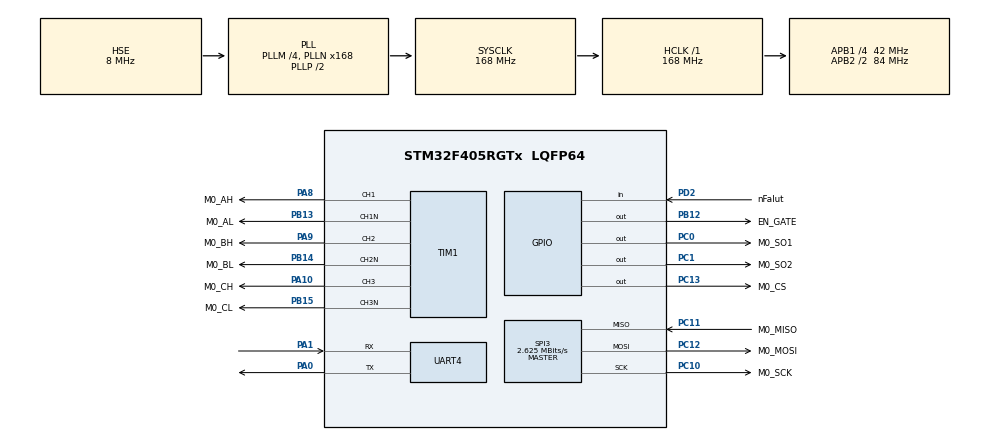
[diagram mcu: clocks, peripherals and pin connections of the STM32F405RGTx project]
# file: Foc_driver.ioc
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Dma.Request0=SPI3_RX
Dma.Request1=SPI3_TX
Dma.SPI3_RX.0.Direction=DMA_PERIPH_TO_MEMORY
Dma.SPI3_RX.0.FIFOMode=DMA_FIFOMODE_DISABLE
Dma.SPI3_RX.0.Instance=DMA1_Stream0
Dma.SPI3_RX.0.MemDataAlignment=DMA_MDATAALIGN_HALFWORD
Dma.SPI3_RX.0.MemInc=DMA_MINC_ENABLE
Dma.SPI3_RX.0.Mode=DMA_NORMAL
Dma.SPI3_RX.0.PeriphDataAlignment=DMA_PDATAALIGN_HALFWORD
Dma.SPI3_RX.0.PeriphInc=DMA_PINC_DISABLE
Dma.SPI3_RX.0.Priority=DMA_PRIORITY_MEDIUM
Dma.SPI3_TX.1.Direction=DMA_MEMORY_TO_PERIPH
Dma.SPI3_TX.1.FIFOMode=DMA_FIFOMODE_DISABLE
Dma.SPI3_TX.1.Instance=DMA1_Stream5
Dma.SPI3_TX.1.MemDataAlignment=DMA_MDATAALIGN_HALFWORD
Dma.SPI3_TX.1.MemInc=DMA_MINC_ENABLE
Dma.SPI3_TX.1.Mode=DMA_NORMAL
Dma.SPI3_TX.1.PeriphDataAlignment=DMA_PDATAALIGN_HALFWORD
Dma.SPI3_TX.1.PeriphInc=DMA_PINC_DISABLE
Dma.SPI3_TX.1.Priority=DMA_PRIORITY_MEDIUM
Mcu.Family=STM32F4
Mcu.Name=STM32F405RGTx
Mcu.Package=LQFP64
Mcu.UserConstants=TIM_1_8_PERIOD_CLOCKS,3500
NVIC.DMA1_Stream0_IRQn=true\:0\:0\:false\:false\:true\:false\:true\:true
NVIC.DMA1_Stream5_IRQn=true\:0\:0\:false\:false\:true\:false\:true\:true
NVIC.PriorityGroup=NVIC_PRIORITYGROUP_4
NVIC.SPI3_IRQn=true\:5\:0\:true\:false\:true\:true\:true\:true
NVIC.TIM8_TRG_COM_TIM14_IRQn=true\:15\:0\:false\:false\:true\:false\:true\:true
NVIC.TimeBase=TIM8_TRG_COM_TIM14_IRQn
NVIC.TimeBaseIP=TIM14
NVIC.UART4_IRQn=true\:0\:0\:false\:false\:true\:true\:true\:true
PA0-WKUP.Mode=Asynchronous
PA0-WKUP.Signal=UART4_TX
PA1.Mode=Asynchronous
PA1.Signal=UART4_RX
PA10.GPIO_Label=M0_CH
PA10.Signal=S_TIM1_CH3
PA13.Mode=Serial_Wire
PA13.Signal=SYS_JTMS-SWDIO
PA14.Mode=Serial_Wire
PA14.Signal=SYS_JTCK-SWCLK
PA8.GPIO_Label=M0_AH
PA8.Signal=S_TIM1_CH1
PA9.GPIO_Label=M0_BH
PA9.Signal=S_TIM1_CH2
PB12.GPIO_Label=EN_GATE
PB12.Signal=GPIO_Output
PB13.GPIO_Label=M0_AL
PB13.Mode=PWM Generation1 CH1 CH1N
PB13.Signal=TIM1_CH1N
PB14.GPIO_Label=M0_BL
PB14.Mode=PWM Generation2 CH2 CH2N
PB14.Signal=TIM1_CH2N
PB15.GPIO_Label=M0_CL
PB15.Mode=PWM Generation3 CH3 CH3N
PB15.Signal=TIM1_CH3N
PC0.GPIO_Label=M0_SO1
PC0.Signal=GPIO_Output
PC1.GPIO_Label=M0_SO2
PC1.Signal=GPIO_Output
PC10.GPIO_Label=M0_SCK
PC10.GPIO_PuPd=GPIO_PULLUP
PC10.Mode=Full_Duplex_Master
PC10.Signal=SPI3_SCK
PC11.GPIO_Label=M0_MISO
PC11.GPIO_PuPd=GPIO_PULLUP
PC11.Mode=Full_Duplex_Master
PC11.Signal=SPI3_MISO
PC12.GPIO_Label=M0_MOSI
PC12.GPIO_PuPd=GPIO_PULLUP
PC12.Mode=Full_Duplex_Master
PC12.Signal=SPI3_MOSI
PC13-ANTI_TAMP.GPIO_Label=M0_CS
PC13-ANTI_TAMP.Signal=GPIO_Output
PD2.GPIO_Label=nFalut
PD2.GPIO_PuPd=GPIO_PULLUP
PD2.Signal=GPIO_Input
PH0-OSC_IN.Mode=HSE-External-Oscillator
PH0-OSC_IN.Signal=RCC_OSC_IN
PH1-OSC_OUT.Mode=HSE-External-Oscillator
PH1-OSC_OUT.Signal=RCC_OSC_OUT
ProjectManager.HeapSize=0x200
ProjectManager.StackSize=0x400
ProjectManager.TargetToolchain=MDK-ARM V5.32
RCC.48MHZClocksFreq_Value=84000000
RCC.AHBFreq_Value=168000000
RCC.APB1CLKDivider=RCC_HCLK_DIV4
RCC.APB1Freq_Value=42000000
RCC.APB1TimFreq_Value=84000000
RCC.APB2CLKDivider=RCC_HCLK_DIV2
RCC.APB2Freq_Value=84000000
RCC.APB2TimFreq_Value=168000000
RCC.CortexFreq_Value=168000000
RCC.HCLKFreq_Value=168000000
RCC.HSE_VALUE=8000000
RCC.HSI_VALUE=16000000
RCC.LSE_VALUE=32768
RCC.PLLM=4
RCC.PLLN=168
RCC.PLLSourceVirtual=RCC_PLLSOURCE_HSE
RCC.SYSCLKFreq_VALUE=168000000
RCC.SYSCLKSource=RCC_SYSCLKSOURCE_PLLCLK
RCC.VCOOutputFreq_Value=336000000
SH.S_TIM1_CH1.0=TIM1_CH1,PWM Generation1 CH1 CH1N
SH.S_TIM1_CH2.0=TIM1_CH2,PWM Generation2 CH2 CH2N
SH.S_TIM1_CH3.0=TIM1_CH3,PWM Generation3 CH3 CH3N
SPI3.BaudRatePrescaler=SPI_BAUDRATEPRESCALER_16
SPI3.CLKPhase=SPI_PHASE_2EDGE
SPI3.CalculateBaudRate=2.625 MBits/s
SPI3.DataSize=SPI_DATASIZE_16BIT
SPI3.Direction=SPI_DIRECTION_2LINES
SPI3.Mode=SPI_MODE_MASTER
SPI3.VirtualType=VM_MASTER
TIM1.AutoReloadPreload=TIM_AUTORELOAD_PRELOAD_ENABLE
TIM1.Channel-PWM\ Generation1\ CH1\ CH1N=TIM_CHANNEL_1
TIM1.Channel-PWM\ Generation2\ CH2\ CH2N=TIM_CHANNEL_2
TIM1.Channel-PWM\ Generation3\ CH3\ CH3N=TIM_CHANNEL_3
TIM1.DeadTime=20
TIM1.OCMode_PWM-PWM\ Generation1\ CH1\ CH1N=TIM_OCMODE_PWM2
TIM1.OCMode_PWM-PWM\ Generation2\ CH2\ CH2N=TIM_OCMODE_PWM2
TIM1.OCMode_PWM-PWM\ Generation3\ CH3\ CH3N=TIM_OCMODE_PWM2
TIM1.OffStateIDLEMode=TIM_OSSI_ENABLE
TIM1.OffStateRunMode=TIM_OSSR_ENABLE
TIM1.Period=TIM_1_8_PERIOD_CLOCKS
TIM1.TIM_MasterOutputTrigger=TIM_TRGO_UPDATE
UART4.VirtualMode=Asynchronous
VP_SYS_VS_tim14.Mode=TIM14
board=custom

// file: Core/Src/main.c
/* USER CODE BEGIN Header */
/**
  ******************************************************************************
  * @file           : main.c
  * @brief          : Main program body
  ******************************************************************************
  * @attention
  *
  * Copyright (c) 2023 STMicroelectronics.
  * All rights reserved.
  *
  * This software is licensed under terms that can be found in the LICENSE file
  * in the root directory of this software component.
  * If no LICENSE file comes with this software, it is provided AS-IS.
  *
  ******************************************************************************
  */
/* USER CODE END Header */
#include "main.h"
#include "dma.h"
#include "spi.h"
#include "tim.h"
#include "usart.h"
#include "gpio.h"

/* USER CODE BEGIN Includes */
#include "drv8303.h"
/* USER CODE END Includes */

void SystemClock_Config(void);

int main(void)
{

  /* MCU Configuration--------------------------------------------------------*/

  /* Reset of all peripherals, Initializes the Flash interface and the Systick. */
  HAL_Init();

  /* Configure the system clock */
  SystemClock_Config();

  /* Initialize all configured peripherals */
  MX_GPIO_Init();
  MX_DMA_Init();
  MX_SPI3_Init();
  MX_TIM1_Init();
  MX_UART4_Init();
  /* USER CODE BEGIN 2 */
	Drv8303_Init();
	int i=0;
  /* USER CODE END 2 */

  /* Infinite loop */
  while (1)
  {

    /* USER CODE BEGIN 3 */
		i++;
  }
  /* USER CODE END 3 */
}

void SystemClock_Config(void)
{
  RCC_OscInitTypeDef RCC_OscInitStruct = {0};
  RCC_ClkInitTypeDef RCC_ClkInitStruct = {0};

  /** Configure the main internal regulator output voltage
  */
  __HAL_RCC_PWR_CLK_ENABLE();
  __HAL_PWR_VOLTAGESCALING_CONFIG(PWR_REGULATOR_VOLTAGE_SCALE1);

  /** Initializes the RCC Oscillators according to the specified parameters
  * in the RCC_OscInitTypeDef structure.
  */
  RCC_OscInitStruct.OscillatorType = RCC_OSCILLATORTYPE_HSE;
  RCC_OscInitStruct.HSEState = RCC_HSE_ON;
  RCC_OscInitStruct.PLL.PLLState = RCC_PLL_ON;
  RCC_OscInitStruct.PLL.PLLSource = RCC_PLLSOURCE_HSE;
  RCC_OscInitStruct.PLL.PLLM = 4;
  RCC_OscInitStruct.PLL.PLLN = 168;
  RCC_OscInitStruct.PLL.PLLP = RCC_PLLP_DIV2;
  RCC_OscInitStruct.PLL.PLLQ = 4;
  if (HAL_RCC_OscConfig(&RCC_OscInitStruct) != HAL_OK)
  {
    Error_Handler();
  }

  /** Initializes the CPU, AHB and APB buses clocks
  */
  RCC_ClkInitStruct.ClockType = RCC_CLOCKTYPE_HCLK|RCC_CLOCKTYPE_SYSCLK
                              |RCC_CLOCKTYPE_PCLK1|RCC_CLOCKTYPE_PCLK2;
  RCC_ClkInitStruct.SYSCLKSource = RCC_SYSCLKSOURCE_PLLCLK;
  RCC_ClkInitStruct.AHBCLKDivider = RCC_SYSCLK_DIV1;
  RCC_ClkInitStruct.APB1CLKDivider = RCC_HCLK_DIV4;
  RCC_ClkInitStruct.APB2CLKDivider = RCC_HCLK_DIV2;

  if (HAL_RCC_ClockConfig(&RCC_ClkInitStruct, FLASH_LATENCY_5) != HAL_OK)
  {
    Error_Handler();
  }
}

void HAL_TIM_PeriodElapsedCallback(TIM_HandleTypeDef *htim)
{
  if (htim->Instance == TIM14) {
    HAL_IncTick();
  }
}

void Error_Handler(void)
{
  __disable_irq();
  while (1)
  {
  }
}
